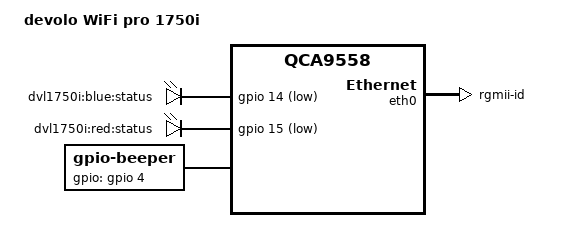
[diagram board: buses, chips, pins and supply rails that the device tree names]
// SPDX-License-Identifier: GPL-2.0-or-later OR MIT

#include "qca9558_devolo_dvl1xxx.dtsi"

/ {
	compatible = "devolo,dvl1750i", "qca,qca9558";
	model = "devolo WiFi pro 1750i";

	aliases {
		led-boot = &led_status_blue;
		led-failsafe = &led_status_red;
		led-running = &led_status_blue;
		led-upgrade = &led_status_red;
	};

	leds {
		compatible = "gpio-leds";

		led_status_blue: status_blue {
			label = "dvl1750i:blue:status";
			gpios = <&gpio 14 GPIO_ACTIVE_LOW>;
			default-state = "on";
		};

		led_status_red: status_red {
			label = "dvl1750i:red:status";
			gpios = <&gpio 15 GPIO_ACTIVE_LOW>;
		};
	};

	beeper {
		compatible = "gpio-beeper";
		gpios = <&gpio 4 GPIO_ACTIVE_HIGH>;
	};
};

&eth0 {
	pll-data = <0xbe000000 0x80000101 0x80001313>;
	phy-mode = "rgmii-id";
};

&gmac_config {
	rxdv-delay = <3>;
	rxd-delay = <3>;
	txen-delay = <3>;
	txd-delay = <3>;
	rgmii-enabled = <1>;
};
